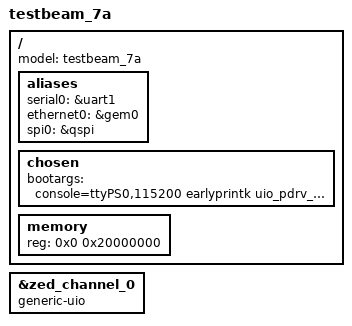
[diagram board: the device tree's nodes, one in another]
/dts-v1/;
/include/ "system-conf.dtsi"
/ {
};

/ {
        model = "testbeam_7a";
        aliases {
                serial0 = &uart1;
                ethernet0 = &gem0;
                spi0 = &qspi;
        };
        chosen {
                bootargs = "console=ttyPS0,115200 earlyprintk uio_pdrv_genirq.of_id=generic-uio";
        };
        memory {
                device_type = "memory";
                reg = <0x0 0x20000000>;
        };
};

&zed_channel_0 {
        compatible = "generic-uio";
};
